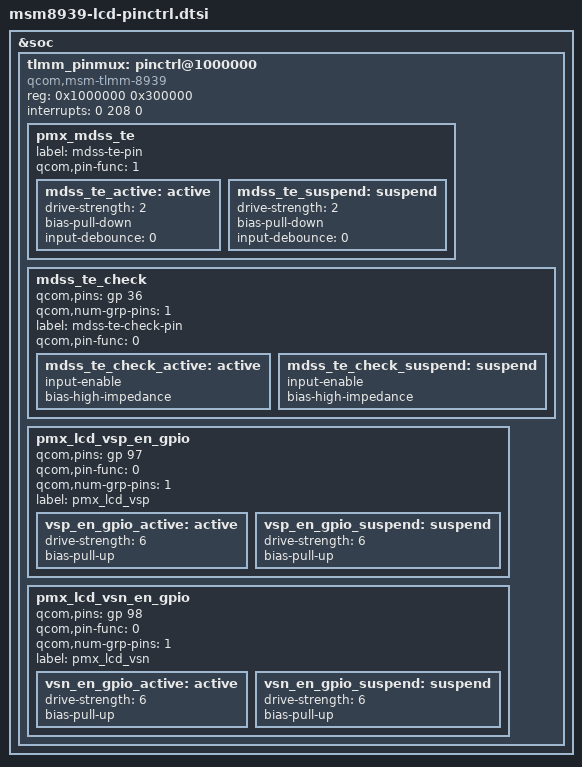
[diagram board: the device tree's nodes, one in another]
/* Copyright (c) 2013-2014, The Linux Foundation. All rights reserved.
 *
 * This program is free software; you can redistribute it and/or modify
 * it under the terms of the GNU General Public License version 2 and
 * only version 2 as published by the Free Software Foundation.
 *
 * This program is distributed in the hope that it will be useful,
 * but WITHOUT ANY WARRANTY; without even the implied warranty of
 * MERCHANTABILITY or FITNESS FOR A PARTICULAR PURPOSE.  See the
 * GNU General Public License for more details.
 */

&soc {
	tlmm_pinmux: pinctrl@1000000 {
		compatible = "qcom,msm-tlmm-8939", "qcom,msm-tlmm-8916";
		reg = <0x1000000 0x300000>;
		interrupts = <0 208 0>;

		pmx_mdss_te: pmx_mdss_te {
			label = "mdss-te-pin";
			qcom,pin-func = <1>;
			mdss_te_active: active {
				drive-strength = <2>; /* 2 mA */
				bias-pull-down; /* pull down */
				input-debounce = <0>;
			};
			mdss_te_suspend: suspend {
				drive-strength = <2>; /* 2 mA */
				bias-pull-down; /* pull down */
				input-debounce = <0>;
			};
		};

		mdss_te_check {
			qcom,pins = <&gp 36>;
			qcom,num-grp-pins = <1>;
			label = "mdss-te-check-pin";
			qcom,pin-func = <0>;
			mdss_te_check_active: active {
				input-enable;
				bias-high-impedance;
			};
			mdss_te_check_suspend: suspend {
				input-enable;
				bias-high-impedance;
			};
		};

		pmx_lcd_vsp_en_gpio{
			qcom,pins = <&gp 97>;
			qcom,pin-func = <0>;
			qcom,num-grp-pins = <1>;
			label = "pmx_lcd_vsp";

			vsp_en_gpio_active: active {
				drive-strength = <6>;
				bias-pull-up;
			};

			vsp_en_gpio_suspend: suspend {
				drive-strength = <6>;
				bias-pull-up;
			};
		};

		pmx_lcd_vsn_en_gpio{
			qcom,pins = <&gp 98>;
			qcom,pin-func = <0>;
			qcom,num-grp-pins = <1>;
			label = "pmx_lcd_vsn";

			vsn_en_gpio_active: active {
				drive-strength = <6>;
				bias-pull-up;
			};

			vsn_en_gpio_suspend: suspend {
				drive-strength = <6>;
				bias-pull-up;
			};
		};

	};
};


